# NUC200AE_v1 register map
File version: 1.0
Registers are 32-bit, read-write, reset 0x0 unless marked. A register's access mark holds for its fields unless they carry their own. Offsets are from the block's base; [hi:lo] are bit positions.

## SC0 — SC Register Map
Base 0x40190000
Same registers: SC1 0x40194000, SC2 0x40198000
0x00 SC_RBR ro reset not defined — SC Receiving Buffer Register.
  [7:0] RBR — Receiving Buffer. By reading RBR, the SC will return an 8-bit received data.
0x00 SC_THR wo reset not defined (alternate view of SC_RBR) — SC Transmit Holding Register
  [7:0] THR — Transmit Holding Buffer. By writing data to THR, the SC will send out an 8-bit data. Note: If SC_CEN(SC_CTL[0]) is not enabled, THR cannot be programmed.
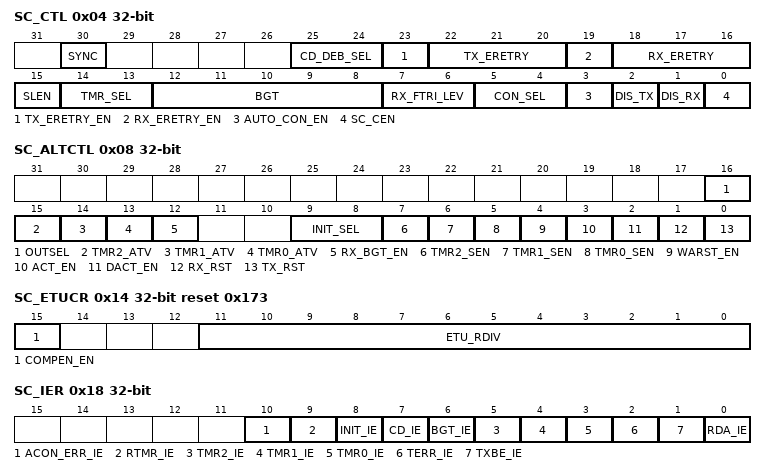
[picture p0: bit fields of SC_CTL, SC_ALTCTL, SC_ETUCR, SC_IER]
0x04 SC_CTL — SC Control Register
  [30] SYNC — SYNC Flag Indicator. Due to synchronization, software should check this bit before writing a new value to RX_ERETRY and TX_ERETRY. Note: This bit is read only.
    0=synchronizing is completion, user can write new data to RX_ERETRY and TX_ERETRY; 1=Last value is synchronizing
  [25:24] CD_DEB_SEL — Card Detect De-Bounce Selection. This field indicates the card detect de-bounce selection.
    0=De-bounce sample card insert once per 384 (128 * 3) SC peripheral clocks and de-bounce sample card removal once per 128 SC peripheral clocks; 1=De-bounce sample card insert once per 192 (64 * 3) SC peripheral clocks and de-bounce sample card removal once per 64 SC peripheral clocks; 2=De-bounce sample card insert once per 96 (32 * 3) SC peripheral clocks and de-bounce sample card removal once per 32 SC peripheral clocks; 3=De-bounce sample card insert once per 48 (16 * 3) SC peripheral clocks and de-bounce sample card removal once per 16 SC peripheral clocks
  [23] TX_ERETRY_EN — TX Error Retry Enable Bit. This bit enables transmitter retry function when parity error has occurred.
    0=TX error retry function Disabled; 1=TX error retry function Enabled
  [22:20] TX_ERETRY — TX Error Retry Count Number. This field indicates the maximum number of transmitter retries that are allowed when parity error has occurred. Note1: The real retry number is TX_ERETRY + 1, so 8 is the maximum retry number. Note2: This field cannot be changed when TX_ERETRY_EN enabled. The change flow is to disable TX_ETRTRY_EN first and then fill in new retry value.
  [19] RX_ERETRY_EN — RX Error Retry Enable Bit. This bit enables receiver retry function when parity error has occurred. Note: Software must fill in the RX_ERETRY value before enabling this bit.
    0=RX error retry function Disabled; 1=RX error retry function Enabled
  [18:16] RX_ERETRY — RX Error Retry Count Number. This field indicates the maximum number of receiver retries that are allowed when parity error has occurred. Note1: The real retry number is RX_ERETRY + 1, so 8 is the maximum retry number. Note2: This field cannot be changed when RX_ERETRY_EN enabled. The change flow is to disable RX_ETRTRY_EN first and then fill in new retry value.
  [15] SLEN — Stop Bit Length. This field indicates the length of stop bit. Note: The default stop bit length is 2. SMC and UART adopts SLEN to program the stop bit length
    0=The stop bit length is 2 ETU; 1=The stop bit length is 1 ETU
  [14:13] TMR_SEL — Timer Selection
    0=All internal timer function Disabled; 1=Internal 24 bit timer Enabled. Software can configure it by setting SC_TMR0 [23:0]. SC_TMR1 and SC_TMR2 will be ignored in this mode; 2=internal 24 bit timer and 8 bit internal timer Enabled. Software can configure the 24 bit timer by setting SC_TMR0 [23:0] and configure the 8 bit timer by setting SC_TMR1[7:0]. SC_TMR2 will be ignored in this mode; 3=Internal 24 bit timer and two 8 bit timers Enabled. Software can configure them by setting SC_TMR0 [23:0], SC_TMR1 [7:0] and SC_TMR2 [7:0]
  [12:8] BGT — Block Guard Time (BGT). Note: The real block guard time is BGT + 1.
  [7:6] RX_FTRI_LEV — Rx Buffer Trigger Level. When the number of bytes in the receiving buffer equals the RX_FTRI_LEV, the RDA_IF will be set (if IER [RDA_IEN] is enabled, an interrupt will be generated).
    0=INTR_RDA Trigger Level with 01 Bytes; 1=INTR_RDA Trigger Level with 02 Bytes; 2=INTR_RDA Trigger Level with 03 Bytes
  [5:4] CON_SEL — Convention Selection. Note: If AUTO_CON_EN(SC_CTL[3]) enabled, this fields are ignored.
    0=Direct convention; 3=Inverse convention
  [3] AUTO_CON_EN — Auto Convention Enable Bit
    0=Auto-convention Disabled; 1=Auto-convention Enabled. When hardware receives TS in answer to reset state and the TS is direct convention, CON_SEL(SC_CTL[5:4]) will be set to 00 automatically, otherwise if the TS is inverse convention, and CON_SEL (SC_CTL[5:4]) will be set to 11
  [2] DIS_TX — TX Transition Disable Bit
    0=The transceiver Enabled; 1=The transceiver Disabled
  [1] DIS_RX — RX Transition Disable Bit. Note: If AUTO_CON_EN (SC_CTL[3])is enabled, these fields must be ignored.
    0=The receiver Enabled; 1=The receiver Disabled
  [0] SC_CEN — SC Engine Enable Bit. Set this bit to 1 to enable SC operation. If this bit is cleared, SC will force all transition to IDLE state.
0x08 SC_ALTCTL — SC Alternate Control Register
  [16] OUTSEL — Smartcard Data Pin Output Mode Selection. Use this bit to select smartcard data pin (SC_DATA) output mode
    0=Quasi mode; 1=Open-drain mode
  [15] TMR2_ATV ro — Internal Timer2 Active State (Read Only). This bit indicates the timer counter status of timer2.
    0=Timer2 is not active; 1=Timer2 is active
  [14] TMR1_ATV ro — Internal Timer1 Active State (Read Only). This bit indicates the timer counter status of timer1.
    0=Timer1 is not active; 1=Timer1 is active
  [13] TMR0_ATV ro — Internal Timer0 Active State (Read Only). This bit indicates the timer counter status of timer0.
    0=Timer0 is not active; 1=Timer0 is active
  [12] RX_BGT_EN — Receiver Block Guard Time Function Enable Bit
    0=Receiver block guard time function Disabled; 1=Receiver block guard time function Enabled
  [9:8] INIT_SEL — Initial Timing Selection. This fields indicates the timing of hardware initial state (activation or warm-reset or deactivation). Unit: SC clock. Activation: refer to SC Activation Sequence in Figure 679. Warm-reset: refer to Warm-Reset Sequence in Figure 680. Deactivation: refer to Deactivation Sequence in Figure 681.
  [7] TMR2_SEN — Internal Timer2 Start Enable Bit. This bit enables Timer 2 to start counting. Software can fill 0 to stop it and set 1 to reload and count. Note3: This field will be cleared by TX_RST(SC_ALTCTL[0]) and RX_RST(SC_ALTCTL[1]). So don't fill this bit, TX_RST(SC_ALTCTL[0]), and RX_RST(SC_ALTCTL[1]) at the same time. Note4: If SC_CEN(SC_CTL[0]) is not enabled, this filed cannot be programmed.
    0=Stops counting; 1=Start counting
  [6] TMR1_SEN — Internal Timer1 Start Enable Bit. This bit enables Timer 1 to start counting. Software can fill 0 to stop it and set 1 to reload and count. Note3: This field will be cleared by TX_RST(SC_ALTCTL[0]) and RX_RST(SC_ALTCTL[1]), so don't fill this bit, TX_RST(SC_ALTCTL[0]), and RX_RST(SC_ALTCTL[1]) at the same time. Note4: If SC_CEN(SC_CTL[0]) is not enabled, this filed cannot be programmed.
    0=Stops counting; 1=Start counting
  [5] TMR0_SEN — Internal Timer0 Start Enable Bit. This bit enables Timer 0 to start counting. Software can fill 0 to stop it and set 1 to reload and count. Note3: This field will be cleared by TX_RST(SC_ALTCTL[0]) and RX_RST(SC_ALTCTL[1]). So don't fill this bit, TX_RST and RX_RST at the same time. Note4: If SC_CEN(SC_CTL[0]) is not enabled, this filed cannot be programmed.
    0=Stops counting; 1=Start counting
  [4] WARST_EN — Warm Reset Sequence Generator Enable Bit. This bit enables SC controller to initiate the card by warm reset sequence. Note1: When the warm reset sequence completed, this bit will be cleared automatically and the INIT_IS(SC_ISR[8]) will be set to 1. Note2: This field will be cleared by TX_RST(SC_ALTCTL[0]) and RX_RST(SC_ALTCTL[1]), so don't fill this bit, TX_RST, and RX_RST at the same time. Note3: If SC_CEN(SC_CTL[0]) is not enabled, this filed cannot be programmed.
    0=No effect; 1=Warm reset sequence generator Enabled
  [3] ACT_EN — Activation Sequence Generator Enable Bit. This bit enables SC controller to initiate the card by activation sequence. Note1: When the activation sequence completed, this bit will be cleared automatically and the INIT_IS(SC_ISR[8]) will be set to 1. Note2: This field will be cleared by TX_RST(SC_ALTCTL[0]) and RX_RST(SC_ALTCTL[1]), so don't fill this bit, TX_RST(SC_ALTCTL[0]), and RX_RST(SC_ALTCTL[1]) at the same time. Note3: If SC_CEN(SC_CTL[0]) is not enabled, this filed cannot be programmed.
    0=No effect; 1=Activation sequence generator Enabled
  [2] DACT_EN — Deactivation Sequence Generator Enable Bit. This bit enables SC controller to initiate the card by deactivation sequence. Note1: When the deactivation sequence completed, this bit will be cleared automatically and the INIT_IS(SC_ISR[8]) will be set to 1. Note2: This field will be cleared by TX_RST (SC_ALTCTL[0]) and RX_RST(SC_ALTCTL[1]). So don't fill this bit, TX_RST, and RX_RST at the same time. Note3: If SC_CEN (SC_CTL[0]) is not enabled, this filed cannot be programmed.
    0=No effect; 1=Deactivation sequence generator Enabled
  [1] RX_RST — Rx Software Reset. When RX_RST is set, all the bytes in the receiver buffer and Rx internal state machine will be cleared. Note: This bit will be auto cleared after reset is complete.
    0=No effect; 1=Reset the Rx internal state machine and pointers
  [0] TX_RST — TX Software Reset. When TX_RST is set, all the bytes in the transmit buffer and TX internal state machine will be cleared. Note: This bit will be auto cleared after reset is complete.
    0=No effect; 1=Reset the TX internal state machine and pointers
0x0C SC_EGTR — SC Extend Guard Time Register
  [7:0] EGT — Extended Guard Time. This field indicates the extended guard timer value. Note: The counter is ETU base and the real extended guard time is EGT.
0x10 SC_RFTMR — SC Receive Buffer Time-out Register
  [8:0] RFTM — SC Receiver Buffer Time-Out (ETU Base). Note1: The counter unit is ETU based and the interval of time-out is RFTM + 0.5. Note2: Fill all 0 to this field indicates to disable this function.
0x14 SC_ETUCR reset 0x173 — SC ETU Control Register
  [15] COMPEN_EN — Compensation Mode Enable Bit. This bit enables clock compensation function. When this bit enabled, hardware will alternate between n clock cycles and n-1 clock cycles, where n is the value to be written into the ETU_RDIV .
    0=Compensation function Disabled; 1=Compensation function Enabled
  [11:0] ETU_RDIV — ETU Rate Divider. The field indicates the clock rate divider. The real ETU is ETU_RDIV + 1. Note: Software can configure this field, but this field must be greater than 0x004.
0x18 SC_IER — SC Interrupt Enable Control Register
  [10] ACON_ERR_IE — Auto Convention Error Interrupt Enable Bit. This field is used for auto-convention error interrupt enable.
    0=Auto-convention error interrupt Disabled; 1=Auto-convention error interrupt Enabled
  [9] RTMR_IE — Receiver Buffer Time-Out Interrupt Enable Bit. This field is used for receiver buffer time-out interrupt enable.
    0=Receiver buffer time-out interrupt Disabled; 1=Receiver buffer time-out interrupt Enabled
  [8] INIT_IE — Initial End Interrupt Enable Bit
    0=Initial end interrupt Disabled; 1=Initial end interrupt Enabled
  [7] CD_IE — Card Detect Interrupt Enable Bit. This field is used for card detect interrupt enable. The card detect status is CD_INS_F(SC_SR[12])
    0=Card detect interrupt Disabled; 1=Card detect interrupt Enabled
  [6] BGT_IE — Block Guard Time Interrupt Enable Bit. This field is used for block guard time interrupt enable.
    0=Block guard time Disabled; 1=Block guard time Enabled
  [5] TMR2_IE — Timer2 Interrupt Enable Bit. This field is used for TMR2 interrupt enable.
    0=Timer2 interrupt Disabled; 1=Timer2 interrupt Enabled
  [4] TMR1_IE — Timer1 Interrupt Enable Bit. This field is used to enable the TMR1 interrupt.
    0=Timer1 interrupt Disabled; 1=Timer1 interrupt Enabled
  [3] TMR0_IE — Timer0 Interrupt Enable Bit. This field is used to enable TMR0 interrupt enable.
    0=Timer0 interrupt Disabled; 1=Timer0 interrupt Enabled
  [2] TERR_IE — Transfer Error Interrupt Enable Bit. This field is used for transfer error interrupt enable. The transfer error states is at SC_SR register which includes receiver break error RX_EBR_F(SC_SR[6]), frame error RX_EFR_F(SC_SR[5]), parity error RX_EPA_F(SC_SR[4]), receiver buffer overflow error RX_OVER_F(SC_SR[0]), transmit buffer overflow error TX_OVER_F(SC_SR[8]), receiver retry over limit error RX_OVER_REERR(SC_SR[22]) and transmitter retry over limit error TX_OVER_REERR(SC_SR[30]).
    0=Transfer error interrupt Disabled; 1=Transfer error interrupt Enabled
  [1] TXBE_IE — Transmit Buffer Empty Interrupt Enable Bit. This field is used for transmit buffer empty interrupt enable.
    0=Transmit buffer empty interrupt Disabled; 1=Transmit buffer empty interrupt Enabled
  [0] RDA_IE — Receive Data Reach Interrupt Enable Bit. This field is used for received data reaching trigger level RX_FTRI_LEV (SC_CTL[7:6]) interrupt enable.
    0=Receive data reach trigger level interrupt Disabled; 1=Receive data reach trigger level interrupt Enabled
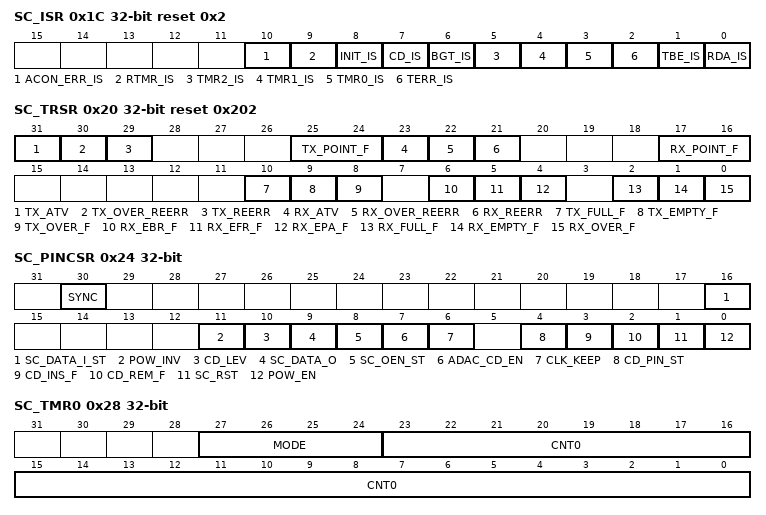
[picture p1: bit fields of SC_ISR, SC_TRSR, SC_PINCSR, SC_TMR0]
0x1C SC_ISR reset 0x2 — SC Interrupt Status Register
  [10] ACON_ERR_IS ro — Auto Convention Error Interrupt Status Flag (Read Only). This field indicates auto convention sequence error. If the received TS at ATR state is neither 0x3B nor 0x3F, this bit will be set. Note: This bit is read only, but it can be cleared by writing 1 to it.
  [9] RTMR_IS ro — Receiver Buffer Time-Out Interrupt Status Flag (Read Only). This field is used for receiver buffer time-out interrupt status flag. Note: This field is the status flag of receiver buffer time-out state. If software wants to clear this bit, software must read all receiver buffer remaining data by reading SC_RBR buffer,
  [8] INIT_IS ro — Initial End Interrupt Status Flag (Read Only). This field is used for activation (ACT_EN(SC_ALTCTL[3])), deactivation (DACT_EN (SC_ALTCTL[2])) and warm reset (WARST_EN (SC_ALTCTL[4])) sequence interrupt status flag. Note: This bit is read only, but it can be cleared by writing 1 to it.
  [7] CD_IS ro — Card Detect Interrupt Status Flag (Read Only). This field is used for card detect interrupt status flag. The card detect status is CD_INS_F (SC_SR[12]) and CD_REM_F(SC_SR[11]). Note: This field is the status flag of CD_INS_F(SC_SR[12]) or CD_REM_F(SC_TRSR[11])]. So if software wants to clear this bit, software must write 1 to this field.
  [6] BGT_IS ro
  [5] TMR2_IS ro — Timer2 Interrupt Status Flag (Read Only). This field is used for TMR2 interrupt status flag. Note: This bit is read only, but it can be cleared by writing 1 to it.
  [4] TMR1_IS ro — Timer1 Interrupt Status Flag (Read Only). This field is used for TMR1 interrupt status flag. Note: This bit is read only, but it can be cleared by writing 1 to it.
  [3] TMR0_IS ro — Timer0 Interrupt Status Flag (Read Only). This field is used for TMR0 interrupt status flag. Note: This bit is read only, but it can be cleared by writing 1 to it.
  [2] TERR_IS ro — Transfer Error Interrupt Status Flag (Read Only). This field is used for transfer error interrupt status flag. The transfer error states is at SC_SR register which includes receiver break error RX_EBR_F(SC_SR[6]), frame error RX_EFR_F(SC_TRSR[5], parity error RX_EPA_F(SC_TRSR[4] and receiver buffer overflow error RX_OVER_F(SC_TRSR[0]), transmit buffer overflow error TX_OVER_F(SC_TRSR[8]), receiver retry over limit error RX_OVER_REERR(SC_TRSR[22] and transmitter retry over limit error TX_OVER_REERR(SC_TRSR[30]). Note: This field is the status flag of RX_EBR_F(SC_TRSR[6]), RX_EFR_F(SC_TRSR[5]), RX_EPA_F(SC_TRSR[4]), RX_OVER_F(SC_TRSR[0]), TX_OVER_F(SC_TRSR[8]), RX_OVER_REERR(SC_TRSR[22]) or TX_OVER_REERR(SC_TRSR[30]). So, if software wants to clear this bit, software must write 1 to each field.
  [1] TBE_IS ro — Transmit Buffer Empty Interrupt Status Flag (Read Only). This field is used for transmit buffer empty interrupt status flag. Note: This field is the status flag of transmit buffer empty state. If software wants to clear this bit, software must write data to THR(SC_THR[7:0]) buffer and then this bit will be cleared automatically.
  [0] RDA_IS ro — Receive Data Reach Interrupt Status Flag (Read Only). This field is used for received data reaching trigger level RX_FTRI_LEV (SC_CTL[7:6]) interrupt status flag. Note: This field is the status flag of received data reaching RX_FTRI_LEV (SC_CTL[7:6]). If software reads data from SC_RBR and receiver buffer data byte number is less than RX_FTRI_LEV (SC_CTL[7:6]), this bit will be cleared automatically.
0x20 SC_TRSR reset 0x202 — SC Status Register
  [31] TX_ATV ro — Transmit In Active Status Flag (Read Only)
    0=This bit is cleared automatically when TX transfer is finished or the last byte transmission has completed; 1=This bit is set by hardware when TX transfer is in active and the STOP bit of the last byte has been transmitted
  [30] TX_OVER_REERR ro — Transmitter Over Retry Error (Read Only). This bit is set by hardware when transmitter re-transmits over retry number limitation. Note: This bit is read only, but it can be cleared by writing 1 to it.
  [29] TX_REERR ro — Transmitter Retry Error (Read Only). This bit is set by hardware when transmitter re-transmits. Note1: This bit is read only, but it can be cleared by writing 1 to it. Note2 This bit is a flag and cannot generate any interrupt to CPU.
  [25:24] TX_POINT_F ro — Transmit Buffer Pointer Status Flag (Read Only). This field indicates the TX buffer pointer status flag. When CPU writes data into SC_THR, TX_POINT_F increases one. When one byte of TX Buffer is transferred to transmitter shift register, TX_POINT_F decreases one.
  [23] RX_ATV ro — Receiver In Active Status Flag (Read Only). This bit is set by hardware when RX transfer is in active. This bit is cleared automatically when RX transfer is finished.
  [22] RX_OVER_REERR ro — Receiver Over Retry Error (Read Only). This bit is set by hardware when RX transfer error retry over retry number limit. Note1: This bit is read only, but it can be cleared by writing 1 to it. Note2: If CPU enables receiver retries function by setting RX_ERETRY_EN (SC_CTL[19]), the RX_EPA_F(SC_TRSR[4]) flag will be ignored (hardware will not set RX_EPA_F(SC_TRSR[4])).
  [21] RX_REERR ro — Receiver Retry Error (Read Only). This bit is set by hardware when RX has any error and retries transfer. Note1: This bit is read only, but it can be cleared by writing 1 to it. Note2 This bit is a flag and cannot generate any interrupt to CPU. Note3: If CPU enables receiver retry function by setting RX_ERETRY_EN (SC_CTL[19]) , the RX_EPA_F(SC_TRSR[4]) flag will be ignored (hardware will not set RX_EPA_F(SC_TRSR[4])).
  [17:16] RX_POINT_F ro — Receiver Buffer Pointer Status Flag (Read Only). This field indicates the RX buffer pointer status flag. When SC receives one byte from external device, RX_POINT_F(SC_SR[17:16]) increases one. When one byte of RX buffer is read by CPU, RX_POINT_F(SC_SR[17:16]) decreases one.
  [10] TX_FULL_F ro — Transmit Buffer Full Status Flag (Read Only). This bit indicates TX buffer full or not.This bit is set when TX pointer is equal to 4, otherwise is cleared by hardware.
  [9] TX_EMPTY_F ro — Transmit Buffer Empty Status Flag (Read Only). This bit indicates TX buffer empty or not. When the last byte of TX buffer has been transferred to Transmitter Shift Register, hardware sets this bit high. It will be cleared when writing data into THR(SC_THR[7:0]) (TX buffer not empty).
  [8] TX_OVER_F ro — TX Overflow Error Interrupt Status Flag (Read Only). If TX buffer is full, an additional write to THR(SC_THR[7:0]) will cause this bit be set to "1" by hardware. Note: This bit is read only, but it can be cleared by writing 1 to it.
  [6] RX_EBR_F ro — Receiver Break Error Status Flag (Read Only). This bit is set to logic 1 whenever the received data input (RX) held in the "spacing state" (logic 0) is longer than a full word transmission time (that is, the total time of "start bit" + data bits + parity + stop bits). . Note1: This bit is read only, but it can be cleared by writing 1 to it. Note2: If CPU sets receiver retries function by setting RX_ERETRY_EN(SC_CTL[19]) , hardware will not set this flag.
  [5] RX_EFR_F ro — Receiver Frame Error Status Flag (Read Only). This bit is set to logic 1 whenever the received character does not have a valid "stop bit" (that is, the stop bit following the last data bit or parity bit is detected as logic 0). Note1: This bit is read only, but it can be cleared by writing 1 to it. Note2: If CPU sets receiver retries function by setting RX_ERETRY_EN(SC_CTL[19]) , hardware will not set this flag.
  [4] RX_EPA_F ro — Receiver Parity Error Status Flag (Read Only). This bit is set to logic 1 whenever the received character does not have a valid "parity bit". Note1: This bit is read only, but it can be cleared by writing 1 to it. Note2: If CPU sets receiver retries function by setting RX_ERETRY_EN(SC_CTL[19]) , hardware will not set this flag.
  [2] RX_FULL_F ro — Receiver Buffer Full Status Flag (Read Only). This bit indicates RX buffer full or not. This bit is set when RX pointer is equal to 4, otherwise it is cleared by hardware.
  [1] RX_EMPTY_F ro — Receiver Buffer Empty Status Flag(Read Only). This bit indicates RX buffer empty or not. When the last byte of Rx buffer has been read by CPU, hardware sets this bit high. It will be cleared when SC receives any new data.
  [0] RX_OVER_F ro — RX Overflow Error Status Flag (Read Only). This bit is set when RX buffer overflow. If the number of received bytes is greater than Rx Buffer size (4 bytes), this bit will be set. Note: This bit is read only, but it can be cleared by writing 1 to it.
0x24 SC_PINCSR (reset mask 0xFFFFFF0F) — SC Pin Control State Register
  [30] SYNC — SYNC Flag Indicator. Due to synchronization, software should check this bit when writing a new value to SC_PINCSR register. Note: This bit is read only.
    0=Synchronizing is completion, user can write new data to SC_PINCSR register; 1=Last value is synchronizing
  [16] SC_DATA_I_ST ro — SC Data Pin Status (Read Only). This bit is the pin status of SC_DATA
    0=The SC_DATA pin is low; 1=The SC_DATA pin is high
  [11] POW_INV — SC_POW Pin Inverse. This bit is used for inverse the SC_POW pin. There are four kinds of combination for SC_POW pin setting by POW_INV(SC_PINCSR[11]) and POW_EN(SC_PINCSR[0]). POW_INV (SC_PINCSR[11]) is bit 1 and POW_EN(SC_PINCSR[0]) is bit 0 for SC_POW_Pin as high or low voltage selection. Note: Software must select POW_INV (SC_PINCSR[11]) before Smart Card is enabled by SC_CEN (SC_CTL[0]).
  [10] CD_LEV — Card Detect Level . Note: Software must select card detect level before Smart Card engine is enabled
    0=When hardware detects the card detect pin from high to low, it indicates a card is detected; 1=When hardware detects the card detect pin from low to high, it indicates a card is detected
  [9] SC_DATA_O — SC Data Output Pin. This bit is the pin status of SC_DATA_O but user can drive SC_DATA_O pin to high or low by setting this bit. Note: When SC is at activation, warm reset or deactivation mode, this bit will be changed automatically. So don't fill this field when SC is in these modes.
    0=Drive SC_DATA_O pin to low; 1=Drive SC_DATA_O pin to high
  [8] SC_OEN_ST ro — SC Data Output Enable Pin Status (Read Only). This bit is the pin status of SC_DATA_OEN
    0=The SC_DATA_OEN pin state at low; 1=The SC_DATA_OEN pin state at high
  [7] ADAC_CD_EN — Auto Deactivation When Card Removal. Note: When the card is removed, hardware will stop any process and then do deactivation sequence (if this bit be setting). If this process completes. Hardware will generate an initial end interrupt to CPU.
    0=Auto deactivation Disabled when hardware detected the card removal; 1=Auto deactivation Enabled when hardware detected the card removal
  [6] CLK_KEEP — SC Clock Enable Bit. Note: When operating in activation, warm reset or deactivation mode, this bit will be changed automatically. So don't fill this field when operating in these modes.
    0=SC clock generation Disabled; 1=SC clock always keeps free running
  [4] CD_PIN_ST ro — Card Detect Status Of SC_CD Pin Status (Read Only). This bit is the pin status flag of SC_CD
    0=The SC_CD pin state at low; 1=The SC_CD pin state at high
  [3] CD_INS_F ro — Card Detect Insert Status Of SC_CD Pin (Read Only). This bit is set whenever card has been inserted. Note1: This bit is read only, but it can be cleared by writing "1" to it. Note2: The card detect engine will start after SC_CEN (SC_CTL[0] )set.
    0=No effect; 1=Card insert
  [2] CD_REM_F ro — Card Detect Removal Status Of SC_CD Pin (Read Only). This bit is set whenever a card has been removed. Note1: This bit is read only, but it can be cleared by writing "1" to it. Note2: Card detect engine will start after SC_CEN (SC_CTL[0] )set.
    0=No effect; 1=Card removed
  [1] SC_RST — SC_RST Pin Signal. This bit is the pin status of SC_RST but user can drive SC_RST pin to high or low by setting this bit. Write this field to drive SC_RST pin. Note: When operating at activation, warm reset or deactivation mode, this bit will be changed automatically. So don't fill this field when operating in these modes.
    0=Drive SC_RST pin to low. SC_RST pin status is low; 1=Drive SC_RST pin to high. SC_RST pin status is high
  [0] POW_EN — SC_POW_EN Pin Signal. Software can set POW_EN (SC_PINCSR[0]) and POW_INV (SC_PINCSR[11])to decide SC_PWR pin is in high or low level. Write this field to drive SC_PWR pin. Refer POW_INV (SC_PINCSR[11]) description for programming SC_PWR pin voltage level. Read this field to get SC_PWR pin status. Note: When operating at activation, warm reset or deactivation mode, this bit will be changed automatically. So don't fill this field when operating in these modes.
    0=SC_PWR pin status is low; 1=SC_PWR pin status is high
0x28 SC_TMR0 — SC Internal Timer Control Register 0
  [27:24] MODE — Timer 0 Operation Mode Selection. This field indicates the internal 24-bit timer operation selection. Refer to 6.14.5.4 for programming Timer0
  [23:0] CNT0 — Timer 0 Counter Value (ETU Base). This field indicates the internal timer operation values.
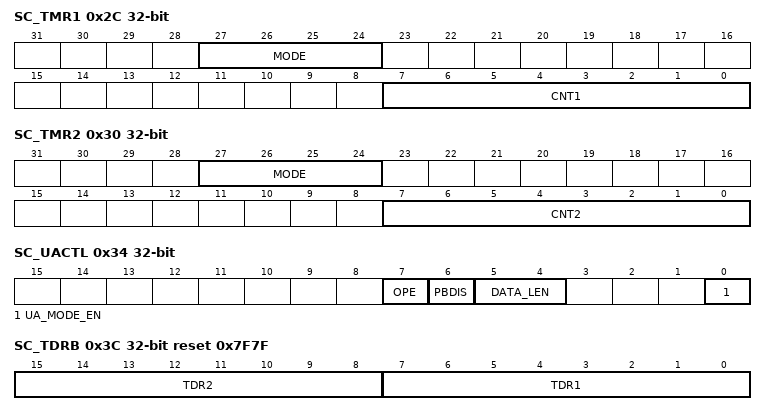
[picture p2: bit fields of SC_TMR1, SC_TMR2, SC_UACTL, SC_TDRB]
0x2C SC_TMR1 — SC Internal Timer Control Register 1
  [27:24] MODE — Timer 1 Operation Mode Selection. This field indicates the internal 8-bit timer operation selection. Refer to 6.14.5.4 for programming Timer1
  [7:0] CNT1 — Timer 1 Counter Value (ETU Base). This field indicates the internal timer operation values.
0x30 SC_TMR2 — SC Internal Timer Control Register 2
  [27:24] MODE — Timer 2 Operation Mode Selection. This field indicates the internal 8-bit timer operation selection. Refer to 6.14.5.4 for programming Timer2
  [7:0] CNT2 — Timer 2 Counter Value (ETU Base). This field indicates the internal timer operation values.
0x34 SC_UACTL — SC UART Mode Control Register.
  [7] OPE — Odd Parity Enable Bit. Note: This bit has effect only when PBDIS bit is '0'.
    0=Even number of logic 1's are transmitted or check the data word and parity bits in receiving mode; 1=Odd number of logic 1's are transmitted or check the data word and parity bits in receiving mode
  [6] PBDIS — Parity Bit Disable Bit. Note: In smart card mode, this field must be '0' (default setting is with parity bit)
    0=Parity bit is generated or checked between the "last data word bit" and "stop bit" of the serial data; 1=Parity bit is not generated (transmitting data) or checked (receiving data) during transfer
  [5:4] DATA_LEN — Data Length. Note: In smart card mode, this DATA_LEN must be '00'
    0=Character Data Length is 8 bits; 1=Character Data Length is 7 bits; 2=Character Data length is 6 bits; 3=Character Data Length is 5 bits
  [0] UA_MODE_EN — UART Mode Enable Bit. Note3: When UART is enabled, hardware will generate a reset to reset FIFO and internal state machine.
    0=Smart Card mode; 1=UART mode
0x38 SC_TDRA ro reset 0x7FF — SC Timer Current Data Register A
  [23:0] TDR0 — Timer0 Current Data Value(Read Only). This field indicates the current count values of timer0.
0x3C SC_TDRB ro reset 0x7F7F — SC Timer Current Data Register B
  [15:8] TDR2 — Timer2 Current Data Value (Read Only). This field indicates the current count values of timer2.
  [7:0] TDR1 — Timer1 Current Data Value(Read Only). This field indicates the current count values of timer1.
